# ESP32C5_RADIO register map
Vendor: Espressif; Series: ESP32-C5; File version: 0.1
Registers are 32-bit, read-write, no defined reset value unless marked. A register's access mark holds for its fields unless they carry their own. Offsets are from the block's base; [hi:lo] are bit positions; {n}, {i} and the like mark numbered series; 'fields as' and 'values as' point back to an identical list.

## MODEM_WIFI_MAC_OBSERVED (part 1 of 2) — Sparse source-qualified word views in the existing owned MMIO aperture; individual meanings and side effects remain unknown.
Base 0x600A4000
0x20 WORD_0020_OPAQUE — Opaque: meaning not established. Aligned 32-bit bus view explicitly addressed by the cited vendor source. No reset or hardware write effect is established.
  [31:0] BITS_0_31_OPAQUE — Opaque: meaning not established. Observed source use; the individual hardware meaning is unknown.
0x28 WORD_0028_OPAQUE — Opaque: meaning not established. Aligned 32-bit bus view explicitly addressed by the cited vendor source. No reset or hardware write effect is established.
  [31:16] BITS_16_31_OPAQUE — Opaque: meaning not established. Observed source use; the individual hardware meaning is unknown.
0x2C WORD_002C_OPAQUE — Opaque: meaning not established. Aligned 32-bit bus view explicitly addressed by the cited vendor source. No reset or hardware write effect is established.
  fields as WORD_0020_OPAQUE
0x38 WORD_0038_OPAQUE — Opaque: meaning not established. Aligned 32-bit bus view explicitly addressed by the cited vendor source. No reset or hardware write effect is established.
  fields as WORD_0020_OPAQUE
0x3C WORD_003C_OPAQUE — Opaque: meaning not established. Aligned 32-bit bus view explicitly addressed by the cited vendor source. No reset or hardware write effect is established.
  [23:0] BITS_0_23_OPAQUE — Opaque: meaning not established. Observed source use; the individual hardware meaning is unknown.
0x40 WORD_0040_OPAQUE ro — Opaque: meaning not established. Aligned 32-bit bus view explicitly addressed by the cited vendor source. No reset or hardware write effect is established.
  fields as WORD_0020_OPAQUE
0x44 WORD_0044_OPAQUE ro — Opaque: meaning not established. Aligned 32-bit bus view explicitly addressed by the cited vendor source. No reset or hardware write effect is established.
  fields as WORD_0020_OPAQUE
0x48 WORD_0048_OPAQUE — Opaque: meaning not established. Aligned 32-bit bus view explicitly addressed by the cited vendor source. No reset or hardware write effect is established.
  fields as WORD_0020_OPAQUE
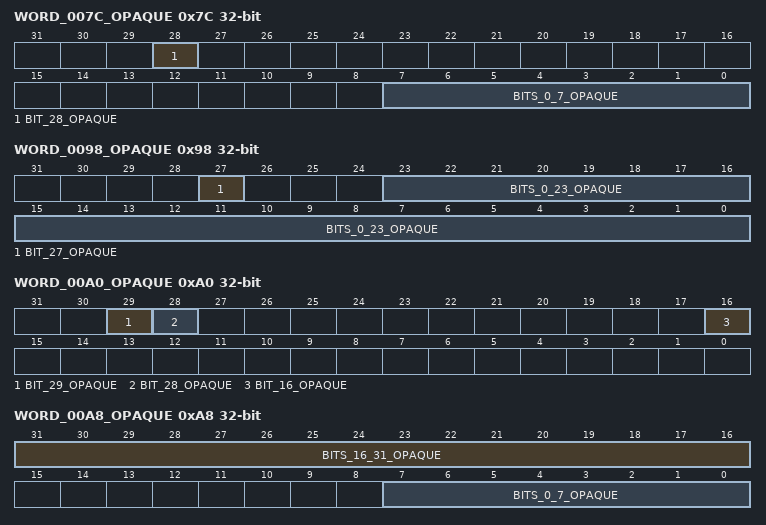
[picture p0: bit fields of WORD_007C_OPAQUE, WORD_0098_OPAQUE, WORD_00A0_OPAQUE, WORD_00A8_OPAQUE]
0x7C WORD_007C_OPAQUE — Opaque: meaning not established. Aligned 32-bit bus view explicitly addressed by the cited vendor source. No reset or hardware write effect is established.
  [28] BIT_28_OPAQUE — Opaque: meaning not established. Observed source use; the individual hardware meaning is unknown.
  [7:0] BITS_0_7_OPAQUE — Opaque: meaning not established. Observed source use; the individual hardware meaning is unknown.
0x80 WORD_0080_OPAQUE — Opaque: meaning not established. Aligned 32-bit bus view explicitly addressed by the cited vendor source. No reset or hardware write effect is established.
  fields as WORD_0020_OPAQUE
0x84 WORD_0084_OPAQUE — Opaque: meaning not established. Aligned 32-bit bus view explicitly addressed by the cited vendor source. No reset or hardware write effect is established.
  fields as WORD_0020_OPAQUE
0x88 WORD_0088_OPAQUE ro — Opaque: meaning not established. Aligned 32-bit bus view explicitly addressed by the cited vendor source. No reset or hardware write effect is established.
  fields as WORD_0020_OPAQUE
0x8C WORD_008C_OPAQUE ro — Opaque: meaning not established. Aligned 32-bit bus view explicitly addressed by the cited vendor source. No reset or hardware write effect is established.
  fields as WORD_0020_OPAQUE
0x90 WORD_0090_OPAQUE ro — Opaque: meaning not established. Aligned 32-bit bus view explicitly addressed by the cited vendor source. No reset or hardware write effect is established.
  fields as WORD_0020_OPAQUE
0x94 WORD_0094_OPAQUE ro — Opaque: meaning not established. Aligned 32-bit bus view explicitly addressed by the cited vendor source. No reset or hardware write effect is established.
  fields as WORD_0020_OPAQUE
0x98 WORD_0098_OPAQUE — Opaque: meaning not established. Aligned 32-bit bus view explicitly addressed by the cited vendor source. No reset or hardware write effect is established.
  [27] BIT_27_OPAQUE — Opaque: meaning not established. Observed source use; the individual hardware meaning is unknown.
  [23:0] BITS_0_23_OPAQUE — Opaque: meaning not established. Observed source use; the individual hardware meaning is unknown.
0x9C WORD_009C_OPAQUE — Opaque: meaning not established. Aligned 32-bit bus view explicitly addressed by the cited vendor source. No reset or hardware write effect is established.
  [3:2] BITS_2_3_OPAQUE — Opaque: meaning not established. Observed source use; the individual hardware meaning is unknown.
0xA0 WORD_00A0_OPAQUE — Opaque: meaning not established. Aligned 32-bit bus view explicitly addressed by the cited vendor source. No reset or hardware write effect is established.
  [29] BIT_29_OPAQUE — Opaque: meaning not established. Observed source use; the individual hardware meaning is unknown.
  [28] BIT_28_OPAQUE — Opaque: meaning not established. Observed source use; the individual hardware meaning is unknown.
  [16] BIT_16_OPAQUE — Opaque: meaning not established. Observed source use; the individual hardware meaning is unknown.
0xA4 WORD_00A4_OPAQUE — Opaque: meaning not established. Aligned 32-bit bus view explicitly addressed by the cited vendor source. No reset or hardware write effect is established.
  [15:12] BITS_12_15_OPAQUE — Opaque: meaning not established. Observed source use; the individual hardware meaning is unknown.
0xA8 WORD_00A8_OPAQUE ro — Opaque: meaning not established. Aligned 32-bit bus view explicitly addressed by the cited vendor source. No reset or hardware write effect is established.
  [31:16] BITS_16_31_OPAQUE — Opaque: meaning not established. Observed source use; the individual hardware meaning is unknown.
  [7:0] BITS_0_7_OPAQUE — Opaque: meaning not established. Observed source use; the individual hardware meaning is unknown.
0xAC WORD_00AC_OPAQUE ro — Opaque: meaning not established. Aligned 32-bit bus view explicitly addressed by the cited vendor source. No reset or hardware write effect is established.
  fields as WORD_0020_OPAQUE
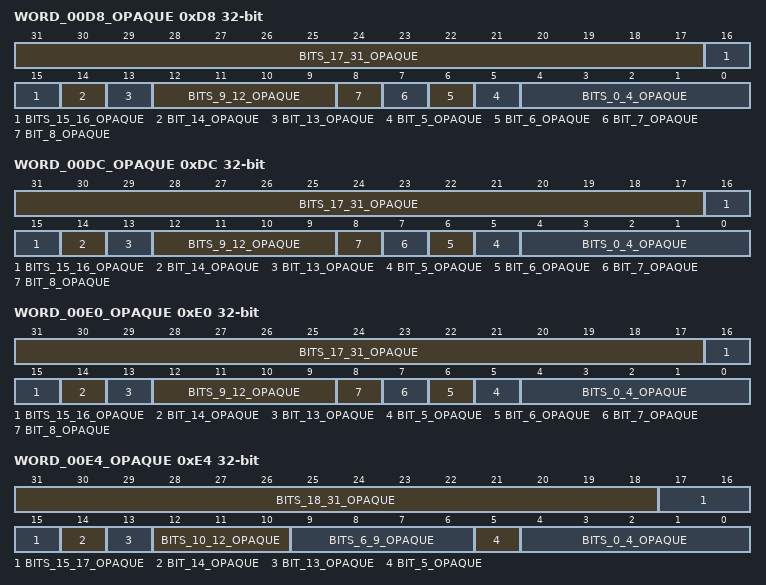
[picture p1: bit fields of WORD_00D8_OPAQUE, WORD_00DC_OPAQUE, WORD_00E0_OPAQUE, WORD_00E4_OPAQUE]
0xD8 WORD_00D8_OPAQUE — Opaque: meaning not established. Aligned 32-bit bus view explicitly addressed by the cited vendor source. No reset or hardware write effect is established.
  [31:17] BITS_17_31_OPAQUE — Opaque: meaning not established. Observed source use; the individual hardware meaning is unknown.
  [16:15] BITS_15_16_OPAQUE — Opaque: meaning not established. Observed source use; the individual hardware meaning is unknown.
  [14] BIT_14_OPAQUE — Opaque: meaning not established. Observed source use; the individual hardware meaning is unknown.
  [13] BIT_13_OPAQUE — Opaque: meaning not established. Observed source use; the individual hardware meaning is unknown.
  [12:9] BITS_9_12_OPAQUE — Opaque: meaning not established. Observed source use; the individual hardware meaning is unknown.
  [n] BIT_{n}_OPAQUE (n=5..8) — Opaque: meaning not established. Observed source use; the individual hardware meaning is unknown.
  [4:0] BITS_0_4_OPAQUE — Opaque: meaning not established. Observed source use; the individual hardware meaning is unknown.
0xDC WORD_00DC_OPAQUE — Opaque: meaning not established. Aligned 32-bit bus view explicitly addressed by the cited vendor source. No reset or hardware write effect is established.
  fields as WORD_00D8_OPAQUE
0xE0 WORD_00E0_OPAQUE — Opaque: meaning not established. Aligned 32-bit bus view explicitly addressed by the cited vendor source. No reset or hardware write effect is established.
  fields as WORD_00D8_OPAQUE
0xE4 WORD_00E4_OPAQUE — Opaque: meaning not established. Aligned 32-bit bus view explicitly addressed by the cited vendor source. No reset or hardware write effect is established.
  [31:18] BITS_18_31_OPAQUE — Opaque: meaning not established. Observed source use; the individual hardware meaning is unknown.
  [17:15] BITS_15_17_OPAQUE — Opaque: meaning not established. Observed source use; the individual hardware meaning is unknown.
  [14] BIT_14_OPAQUE — Opaque: meaning not established. Observed source use; the individual hardware meaning is unknown.
  [13] BIT_13_OPAQUE — Opaque: meaning not established. Observed source use; the individual hardware meaning is unknown.
  [12:10] BITS_10_12_OPAQUE — Opaque: meaning not established. Observed source use; the individual hardware meaning is unknown.
  [9:6] BITS_6_9_OPAQUE — Opaque: meaning not established. Observed source use; the individual hardware meaning is unknown.
  [5] BIT_5_OPAQUE — Opaque: meaning not established. Observed source use; the individual hardware meaning is unknown.
  [4:0] BITS_0_4_OPAQUE — Opaque: meaning not established. Observed source use; the individual hardware meaning is unknown.
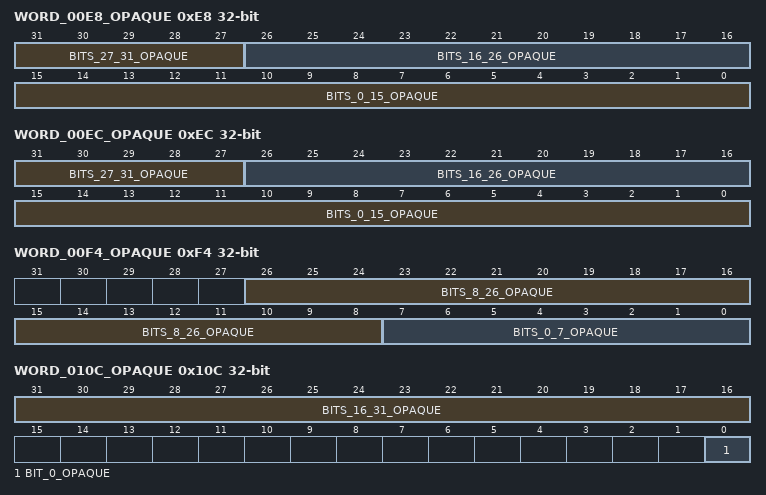
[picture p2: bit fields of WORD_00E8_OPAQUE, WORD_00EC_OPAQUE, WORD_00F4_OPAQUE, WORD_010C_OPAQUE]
0xE8 WORD_00E8_OPAQUE — Opaque: meaning not established. Aligned 32-bit bus view explicitly addressed by the cited vendor source. No reset or hardware write effect is established.
  [31:27] BITS_27_31_OPAQUE — Opaque: meaning not established. Observed source use; the individual hardware meaning is unknown.
  [26:16] BITS_16_26_OPAQUE — Opaque: meaning not established. Observed source use; the individual hardware meaning is unknown.
  [15:0] BITS_0_15_OPAQUE — Opaque: meaning not established. Observed source use; the individual hardware meaning is unknown.
0xEC WORD_00EC_OPAQUE — Opaque: meaning not established. Aligned 32-bit bus view explicitly addressed by the cited vendor source. No reset or hardware write effect is established.
  fields as WORD_00E8_OPAQUE
0xF4 WORD_00F4_OPAQUE — Opaque: meaning not established. Aligned 32-bit bus view explicitly addressed by the cited vendor source. No reset or hardware write effect is established.
  [26:8] BITS_8_26_OPAQUE — Opaque: meaning not established. Observed source use; the individual hardware meaning is unknown.
  [7:0] BITS_0_7_OPAQUE — Opaque: meaning not established. Observed source use; the individual hardware meaning is unknown.
0xFC WORD_00FC_OPAQUE — Opaque: meaning not established. Aligned 32-bit bus view explicitly addressed by the cited vendor source. No reset or hardware write effect is established.
  fields as WORD_0020_OPAQUE
0x100 WORD_0100_OPAQUE — Opaque: meaning not established. Aligned 32-bit bus view explicitly addressed by the cited vendor source. No reset or hardware write effect is established.
  fields as WORD_0020_OPAQUE
0x104 WORD_0104_OPAQUE — Opaque: meaning not established. Aligned 32-bit bus view explicitly addressed by the cited vendor source. No reset or hardware write effect is established.
  fields as WORD_0028_OPAQUE
0x108 WORD_0108_OPAQUE — Opaque: meaning not established. Aligned 32-bit bus view explicitly addressed by the cited vendor source. No reset or hardware write effect is established.
  fields as WORD_0020_OPAQUE
0x10C WORD_010C_OPAQUE — Opaque: meaning not established. Aligned 32-bit bus view explicitly addressed by the cited vendor source. No reset or hardware write effect is established.
  [31:16] BITS_16_31_OPAQUE — Opaque: meaning not established. Observed source use; the individual hardware meaning is unknown.
  [0] BIT_0_OPAQUE — Opaque: meaning not established. Observed source use; the individual hardware meaning is unknown.
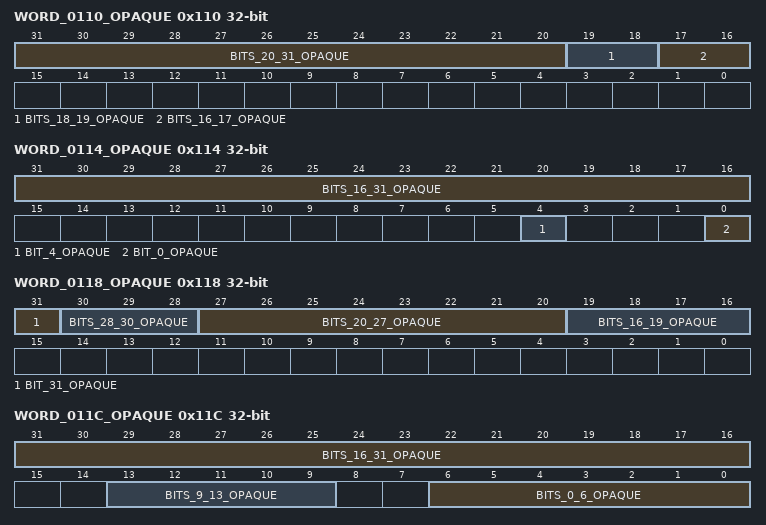
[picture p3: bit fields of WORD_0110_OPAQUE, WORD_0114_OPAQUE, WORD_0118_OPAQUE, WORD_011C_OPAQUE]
0x110 WORD_0110_OPAQUE — Opaque: meaning not established. Aligned 32-bit bus view explicitly addressed by the cited vendor source. No reset or hardware write effect is established.
  [31:20] BITS_20_31_OPAQUE — Opaque: meaning not established. Observed source use; the individual hardware meaning is unknown.
  [19:18] BITS_18_19_OPAQUE — Opaque: meaning not established. Observed source use; the individual hardware meaning is unknown.
  [17:16] BITS_16_17_OPAQUE — Opaque: meaning not established. Observed source use; the individual hardware meaning is unknown.
0x114 WORD_0114_OPAQUE — Opaque: meaning not established. Aligned 32-bit bus view explicitly addressed by the cited vendor source. No reset or hardware write effect is established.
  [31:16] BITS_16_31_OPAQUE — Opaque: meaning not established. Observed source use; the individual hardware meaning is unknown.
  [4] BIT_4_OPAQUE — Opaque: meaning not established. Observed source use; the individual hardware meaning is unknown.
  [0] BIT_0_OPAQUE — Opaque: meaning not established. Observed source use; the individual hardware meaning is unknown.
0x118 WORD_0118_OPAQUE — Opaque: meaning not established. Aligned 32-bit bus view explicitly addressed by the cited vendor source. No reset or hardware write effect is established.
  [31] BIT_31_OPAQUE — Opaque: meaning not established. Observed source use; the individual hardware meaning is unknown.
  [30:28] BITS_28_30_OPAQUE — Opaque: meaning not established. Observed source use; the individual hardware meaning is unknown.
  [27:20] BITS_20_27_OPAQUE — Opaque: meaning not established. Observed source use; the individual hardware meaning is unknown.
  [19:16] BITS_16_19_OPAQUE — Opaque: meaning not established. Observed source use; the individual hardware meaning is unknown.
0x11C WORD_011C_OPAQUE — Opaque: meaning not established. Aligned 32-bit bus view explicitly addressed by the cited vendor source. No reset or hardware write effect is established.
  [31:16] BITS_16_31_OPAQUE — Opaque: meaning not established. Observed source use; the individual hardware meaning is unknown.
  [13:9] BITS_9_13_OPAQUE — Opaque: meaning not established. Observed source use; the individual hardware meaning is unknown.
  [6:0] BITS_0_6_OPAQUE — Opaque: meaning not established. Observed source use; the individual hardware meaning is unknown.
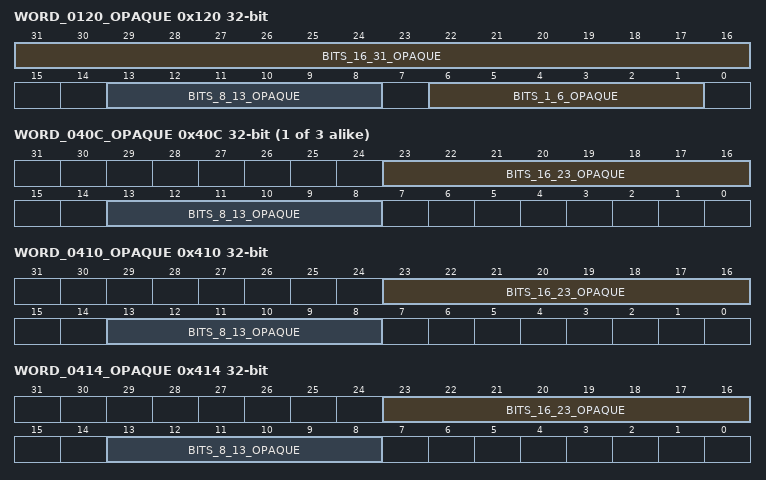
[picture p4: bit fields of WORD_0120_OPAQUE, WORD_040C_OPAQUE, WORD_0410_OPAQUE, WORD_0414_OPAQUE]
0x120 WORD_0120_OPAQUE — Opaque: meaning not established. Aligned 32-bit bus view explicitly addressed by the cited vendor source. No reset or hardware write effect is established.
  [31:16] BITS_16_31_OPAQUE — Opaque: meaning not established. Observed source use; the individual hardware meaning is unknown.
  [13:8] BITS_8_13_OPAQUE — Opaque: meaning not established. Observed source use; the individual hardware meaning is unknown.
  [6:1] BITS_1_6_OPAQUE — Opaque: meaning not established. Observed source use; the individual hardware meaning is unknown.
0x294 WORD_0294_OPAQUE — Opaque: meaning not established. Aligned 32-bit bus view explicitly addressed by the cited vendor source. No reset or hardware write effect is established.
  fields as WORD_0020_OPAQUE
0x298 WORD_0298_OPAQUE — Opaque: meaning not established. Aligned 32-bit bus view explicitly addressed by the cited vendor source. No reset or hardware write effect is established.
  fields as WORD_0020_OPAQUE
0x29C WORD_029C_OPAQUE ro — Opaque: meaning not established. Aligned 32-bit bus view explicitly addressed by the cited vendor source. No reset or hardware write effect is established.
  fields as WORD_0020_OPAQUE
0x2A0 WORD_02A0_OPAQUE ro — Opaque: meaning not established. Aligned 32-bit bus view explicitly addressed by the cited vendor source. No reset or hardware write effect is established.
  fields as WORD_0020_OPAQUE
0x2A4 WORD_02A4_OPAQUE ro — Opaque: meaning not established. Aligned 32-bit bus view explicitly addressed by the cited vendor source. No reset or hardware write effect is established.
  fields as WORD_0020_OPAQUE
0x2A8 WORD_02A8_OPAQUE ro — Opaque: meaning not established. Aligned 32-bit bus view explicitly addressed by the cited vendor source. No reset or hardware write effect is established.
  fields as WORD_0020_OPAQUE
0x2AC WORD_02AC_OPAQUE ro — Opaque: meaning not established. Aligned 32-bit bus view explicitly addressed by the cited vendor source. No reset or hardware write effect is established.
  [19:0] BITS_0_19_OPAQUE — Opaque: meaning not established. Observed source use; the individual hardware meaning is unknown.
0x2B0 WORD_02B0_OPAQUE — Opaque: meaning not established. Aligned 32-bit bus view explicitly addressed by the cited vendor source. No reset or hardware write effect is established.
  fields as WORD_0020_OPAQUE
0x2B8 WORD_02B8_OPAQUE — Opaque: meaning not established. Aligned 32-bit bus view explicitly addressed by the cited vendor source. No reset or hardware write effect is established.
  [31:30] BITS_30_31_OPAQUE — Opaque: meaning not established. Observed source use; the individual hardware meaning is unknown.
0x2FC WORD_02FC_OPAQUE — Opaque: meaning not established. Aligned 32-bit bus view explicitly addressed by the cited vendor source. No reset or hardware write effect is established.
  fields as WORD_0020_OPAQUE
0x300 WORD_0300_OPAQUE ro — Opaque: meaning not established. Aligned 32-bit bus view explicitly addressed by the cited vendor source. No reset or hardware write effect is established.
  fields as WORD_0020_OPAQUE
0x308 WORD_0308_OPAQUE — Opaque: meaning not established. Aligned 32-bit bus view explicitly addressed by the cited vendor source. No reset or hardware write effect is established.
  [1:0] BITS_0_1_OPAQUE — Opaque: meaning not established. Observed source use; the individual hardware meaning is unknown.
0x30C WORD_030C_OPAQUE ro — Opaque: meaning not established. Aligned 32-bit bus view explicitly addressed by the cited vendor source. No reset or hardware write effect is established.
  fields as WORD_0020_OPAQUE
0x310 WORD_0310_OPAQUE ro — Opaque: meaning not established. Aligned 32-bit bus view explicitly addressed by the cited vendor source. No reset or hardware write effect is established.
  [9:0] BITS_0_9_OPAQUE — Opaque: meaning not established. Observed source use; the individual hardware meaning is unknown.
0x314 WORD_0314_OPAQUE ro — Opaque: meaning not established. Aligned 32-bit bus view explicitly addressed by the cited vendor source. No reset or hardware write effect is established.
  fields as WORD_0310_OPAQUE
0x318 WORD_0318_OPAQUE — Opaque: meaning not established. Aligned 32-bit bus view explicitly addressed by the cited vendor source. No reset or hardware write effect is established.
  fields as WORD_0020_OPAQUE
{0x12C+0x10*i} WORD_{i:03}C_OPAQUE ro (i=31..34) — Opaque: meaning not established. Aligned 32-bit bus view explicitly addressed by the cited vendor source. No reset or hardware write effect is established.
  fields as WORD_0310_OPAQUE
0x320 WORD_0320_OPAQUE ro — Opaque: meaning not established. Aligned 32-bit bus view explicitly addressed by the cited vendor source. No reset or hardware write effect is established.
  fields as WORD_0310_OPAQUE
0x324 WORD_0324_OPAQUE ro — Opaque: meaning not established. Aligned 32-bit bus view explicitly addressed by the cited vendor source. No reset or hardware write effect is established.
  fields as WORD_0310_OPAQUE
0x328 WORD_0328_OPAQUE ro — Opaque: meaning not established. Aligned 32-bit bus view explicitly addressed by the cited vendor source. No reset or hardware write effect is established.
  fields as WORD_0310_OPAQUE
0x330 WORD_0330_OPAQUE ro — Opaque: meaning not established. Aligned 32-bit bus view explicitly addressed by the cited vendor source. No reset or hardware write effect is established.
  fields as WORD_0310_OPAQUE
0x334 WORD_0334_OPAQUE ro — Opaque: meaning not established. Aligned 32-bit bus view explicitly addressed by the cited vendor source. No reset or hardware write effect is established.
  fields as WORD_0310_OPAQUE
0x338 WORD_0338_OPAQUE ro — Opaque: meaning not established. Aligned 32-bit bus view explicitly addressed by the cited vendor source. No reset or hardware write effect is established.
  fields as WORD_0310_OPAQUE
0x340 WORD_0340_OPAQUE ro — Opaque: meaning not established. Aligned 32-bit bus view explicitly addressed by the cited vendor source. No reset or hardware write effect is established.
  fields as WORD_0310_OPAQUE
0x344 WORD_0344_OPAQUE ro — Opaque: meaning not established. Aligned 32-bit bus view explicitly addressed by the cited vendor source. No reset or hardware write effect is established.
  fields as WORD_0310_OPAQUE
0x348 WORD_0348_OPAQUE ro — Opaque: meaning not established. Aligned 32-bit bus view explicitly addressed by the cited vendor source. No reset or hardware write effect is established.
  [15:0] BITS_0_15_OPAQUE — Opaque: meaning not established. Observed source use; the individual hardware meaning is unknown.
0x350 WORD_0350_OPAQUE ro — Opaque: meaning not established. Aligned 32-bit bus view explicitly addressed by the cited vendor source. No reset or hardware write effect is established.
  fields as WORD_0310_OPAQUE
0x354 WORD_0354_OPAQUE ro — Opaque: meaning not established. Aligned 32-bit bus view explicitly addressed by the cited vendor source. No reset or hardware write effect is established.
  fields as WORD_0310_OPAQUE
0x358 WORD_0358_OPAQUE ro — Opaque: meaning not established. Aligned 32-bit bus view explicitly addressed by the cited vendor source. No reset or hardware write effect is established.
  fields as WORD_0310_OPAQUE
{0x12C+0x10*i} WORD_{i:03}C_OPAQUE ro (i=35..38) — Opaque: meaning not established. Aligned 32-bit bus view explicitly addressed by the cited vendor source. No reset or hardware write effect is established.
  fields as WORD_0348_OPAQUE
0x360 WORD_0360_OPAQUE ro — Opaque: meaning not established. Aligned 32-bit bus view explicitly addressed by the cited vendor source. No reset or hardware write effect is established.
  fields as WORD_0020_OPAQUE
0x364 WORD_0364_OPAQUE ro — Opaque: meaning not established. Aligned 32-bit bus view explicitly addressed by the cited vendor source. No reset or hardware write effect is established.
  fields as WORD_0348_OPAQUE
0x368 WORD_0368_OPAQUE ro — Opaque: meaning not established. Aligned 32-bit bus view explicitly addressed by the cited vendor source. No reset or hardware write effect is established.
  fields as WORD_0348_OPAQUE
0x370 WORD_0370_OPAQUE ro — Opaque: meaning not established. Aligned 32-bit bus view explicitly addressed by the cited vendor source. No reset or hardware write effect is established.
  fields as WORD_0348_OPAQUE
0x374 WORD_0374_OPAQUE ro — Opaque: meaning not established. Aligned 32-bit bus view explicitly addressed by the cited vendor source. No reset or hardware write effect is established.
  fields as WORD_0348_OPAQUE
0x378 WORD_0378_OPAQUE ro — Opaque: meaning not established. Aligned 32-bit bus view explicitly addressed by the cited vendor source. No reset or hardware write effect is established.
  fields as WORD_0348_OPAQUE
0x380 WORD_0380_OPAQUE ro — Opaque: meaning not established. Aligned 32-bit bus view explicitly addressed by the cited vendor source. No reset or hardware write effect is established.
  fields as WORD_0348_OPAQUE
0x384 WORD_0384_OPAQUE ro — Opaque: meaning not established. Aligned 32-bit bus view explicitly addressed by the cited vendor source. No reset or hardware write effect is established.
  fields as WORD_0348_OPAQUE
0x388 WORD_0388_OPAQUE ro — Opaque: meaning not established. Aligned 32-bit bus view explicitly addressed by the cited vendor source. No reset or hardware write effect is established.
  fields as WORD_0348_OPAQUE
0x390 WORD_0390_OPAQUE ro — Opaque: meaning not established. Aligned 32-bit bus view explicitly addressed by the cited vendor source. No reset or hardware write effect is established.
  fields as WORD_0348_OPAQUE
0x394 WORD_0394_OPAQUE ro — Opaque: meaning not established. Aligned 32-bit bus view explicitly addressed by the cited vendor source. No reset or hardware write effect is established.
  fields as WORD_0020_OPAQUE
0x398 WORD_0398_OPAQUE ro — Opaque: meaning not established. Aligned 32-bit bus view explicitly addressed by the cited vendor source. No reset or hardware write effect is established.
  fields as WORD_0020_OPAQUE
0x39C WORD_039C_OPAQUE ro — Opaque: meaning not established. Aligned 32-bit bus view explicitly addressed by the cited vendor source. No reset or hardware write effect is established.
  [31:24] BITS_24_31_OPAQUE — Opaque: meaning not established. Observed source use; the individual hardware meaning is unknown.
0x3A0 WORD_03A0_OPAQUE ro — Opaque: meaning not established. Aligned 32-bit bus view explicitly addressed by the cited vendor source. No reset or hardware write effect is established.
  fields as WORD_0020_OPAQUE
0x3A4 WORD_03A4_OPAQUE ro — Opaque: meaning not established. Aligned 32-bit bus view explicitly addressed by the cited vendor source. No reset or hardware write effect is established.
  fields as WORD_0020_OPAQUE
0x3A8 WORD_03A8_OPAQUE ro — Opaque: meaning not established. Aligned 32-bit bus view explicitly addressed by the cited vendor source. No reset or hardware write effect is established.
  fields as WORD_0020_OPAQUE
0x3B4 WORD_03B4_OPAQUE ro — Opaque: meaning not established. Aligned 32-bit bus view explicitly addressed by the cited vendor source. No reset or hardware write effect is established.
  fields as WORD_0020_OPAQUE
0x3B8 WORD_03B8_OPAQUE ro — Opaque: meaning not established. Aligned 32-bit bus view explicitly addressed by the cited vendor source. No reset or hardware write effect is established.
  fields as WORD_0020_OPAQUE
0x3BC WORD_03BC_OPAQUE ro — Opaque: meaning not established. Aligned 32-bit bus view explicitly addressed by the cited vendor source. No reset or hardware write effect is established.
  fields as WORD_0020_OPAQUE
0x3C0 WORD_03C0_OPAQUE ro — Opaque: meaning not established. Aligned 32-bit bus view explicitly addressed by the cited vendor source. No reset or hardware write effect is established.
  fields as WORD_0020_OPAQUE
0x400 WORD_0400_OPAQUE — Opaque: meaning not established. Aligned 32-bit bus view explicitly addressed by the cited vendor source. No reset or hardware write effect is established.
  fields as WORD_0020_OPAQUE
0x408 WORD_0408_OPAQUE — Opaque: meaning not established. Aligned 32-bit bus view explicitly addressed by the cited vendor source. No reset or hardware write effect is established.
  fields as WORD_0020_OPAQUE
{0x18C+0x10*i} WORD_{i:03}C_OPAQUE (i=40..42) — Opaque: meaning not established. Aligned 32-bit bus view explicitly addressed by the cited vendor source. No reset or hardware write effect is established.
  [23:16] BITS_16_23_OPAQUE — Opaque: meaning not established. Observed source use; the individual hardware meaning is unknown.
  [13:8] BITS_8_13_OPAQUE — Opaque: meaning not established. Observed source use; the individual hardware meaning is unknown.
0x410 WORD_0410_OPAQUE — Opaque: meaning not established. Aligned 32-bit bus view explicitly addressed by the cited vendor source. No reset or hardware write effect is established.
  fields as WORD_040C_OPAQUE
0x414 WORD_0414_OPAQUE — Opaque: meaning not established. Aligned 32-bit bus view explicitly addressed by the cited vendor source. No reset or hardware write effect is established.
  fields as WORD_040C_OPAQUE
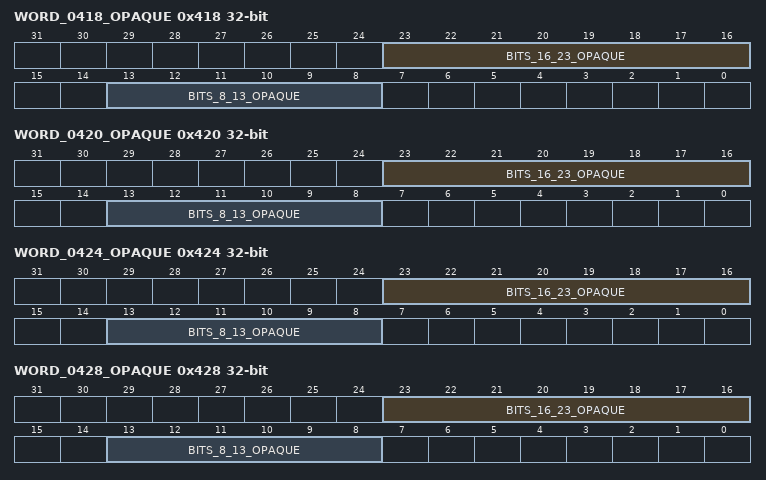
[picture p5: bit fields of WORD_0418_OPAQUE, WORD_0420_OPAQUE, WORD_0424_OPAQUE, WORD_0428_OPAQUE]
0x418 WORD_0418_OPAQUE — Opaque: meaning not established. Aligned 32-bit bus view explicitly addressed by the cited vendor source. No reset or hardware write effect is established.
  fields as WORD_040C_OPAQUE
0x420 WORD_0420_OPAQUE — Opaque: meaning not established. Aligned 32-bit bus view explicitly addressed by the cited vendor source. No reset or hardware write effect is established.
  fields as WORD_040C_OPAQUE
0x424 WORD_0424_OPAQUE — Opaque: meaning not established. Aligned 32-bit bus view explicitly addressed by the cited vendor source. No reset or hardware write effect is established.
  fields as WORD_040C_OPAQUE
0x428 WORD_0428_OPAQUE — Opaque: meaning not established. Aligned 32-bit bus view explicitly addressed by the cited vendor source. No reset or hardware write effect is established.
  fields as WORD_040C_OPAQUE
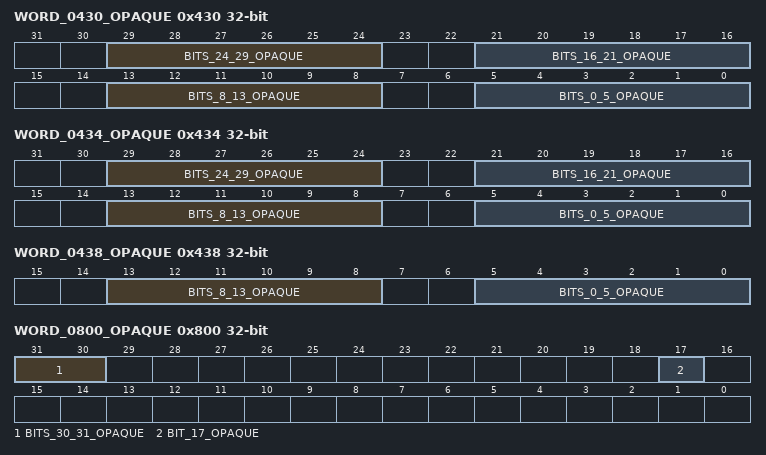
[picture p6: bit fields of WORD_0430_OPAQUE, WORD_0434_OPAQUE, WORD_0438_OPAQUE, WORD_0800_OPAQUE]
0x430 WORD_0430_OPAQUE — Opaque: meaning not established. Aligned 32-bit bus view explicitly addressed by the cited vendor source. No reset or hardware write effect is established.
  [29:24] BITS_24_29_OPAQUE — Opaque: meaning not established. Observed source use; the individual hardware meaning is unknown.
  [21:16] BITS_16_21_OPAQUE — Opaque: meaning not established. Observed source use; the individual hardware meaning is unknown.
  [13:8] BITS_8_13_OPAQUE — Opaque: meaning not established. Observed source use; the individual hardware meaning is unknown.
  [5:0] BITS_0_5_OPAQUE — Opaque: meaning not established. Observed source use; the individual hardware meaning is unknown.
0x434 WORD_0434_OPAQUE — Opaque: meaning not established. Aligned 32-bit bus view explicitly addressed by the cited vendor source. No reset or hardware write effect is established.
  fields as WORD_0430_OPAQUE
0x438 WORD_0438_OPAQUE — Opaque: meaning not established. Aligned 32-bit bus view explicitly addressed by the cited vendor source. No reset or hardware write effect is established.
  [13:8] BITS_8_13_OPAQUE — Opaque: meaning not established. Observed source use; the individual hardware meaning is unknown.
  [5:0] BITS_0_5_OPAQUE — Opaque: meaning not established. Observed source use; the individual hardware meaning is unknown.
0x43C WORD_043C_OPAQUE — Opaque: meaning not established. Aligned 32-bit bus view explicitly addressed by the cited vendor source. No reset or hardware write effect is established.
  fields as WORD_0020_OPAQUE
0x440 WORD_0440_OPAQUE — Opaque: meaning not established. Aligned 32-bit bus view explicitly addressed by the cited vendor source. No reset or hardware write effect is established.
  fields as WORD_0020_OPAQUE
0x444 WORD_0444_OPAQUE — Opaque: meaning not established. Aligned 32-bit bus view explicitly addressed by the cited vendor source. No reset or hardware write effect is established.
  fields as WORD_0020_OPAQUE
0x448 WORD_0448_OPAQUE — Opaque: meaning not established. Aligned 32-bit bus view explicitly addressed by the cited vendor source. No reset or hardware write effect is established.
  fields as WORD_0020_OPAQUE
0x44C WORD_044C_OPAQUE — Opaque: meaning not established. Aligned 32-bit bus view explicitly addressed by the cited vendor source. No reset or hardware write effect is established.
  fields as WORD_0020_OPAQUE
0x458 WORD_0458_OPAQUE — Opaque: meaning not established. Aligned 32-bit bus view explicitly addressed by the cited vendor source. No reset or hardware write effect is established.
  fields as WORD_0020_OPAQUE
0x464 WORD_0464_OPAQUE — Opaque: meaning not established. Aligned 32-bit bus view explicitly addressed by the cited vendor source. No reset or hardware write effect is established.
  fields as WORD_0020_OPAQUE
0x47C WORD_047C_OPAQUE — Opaque: meaning not established. Aligned 32-bit bus view explicitly addressed by the cited vendor source. No reset or hardware write effect is established.
  [23:12] BITS_12_23_OPAQUE — Opaque: meaning not established. Observed source use; the individual hardware meaning is unknown.
0x480 WORD_0480_OPAQUE — Opaque: meaning not established. Aligned 32-bit bus view explicitly addressed by the cited vendor source. No reset or hardware write effect is established.
  [31] BIT_31_OPAQUE — Opaque: meaning not established. Observed source use; the individual hardware meaning is unknown.
0x48C WORD_048C_OPAQUE — Opaque: meaning not established. Aligned 32-bit bus view explicitly addressed by the cited vendor source. No reset or hardware write effect is established.
  fields as WORD_0020_OPAQUE
0x490 WORD_0490_OPAQUE — Opaque: meaning not established. Aligned 32-bit bus view explicitly addressed by the cited vendor source. No reset or hardware write effect is established.
  [31:18] BITS_18_31_OPAQUE — Opaque: meaning not established. Observed source use; the individual hardware meaning is unknown.
0x494 WORD_0494_OPAQUE — Opaque: meaning not established. Aligned 32-bit bus view explicitly addressed by the cited vendor source. No reset or hardware write effect is established.
  [15] BIT_15_OPAQUE — Opaque: meaning not established. Observed source use; the individual hardware meaning is unknown.
0x4C4 WORD_04C4_OPAQUE — Opaque: meaning not established. Aligned 32-bit bus view explicitly addressed by the cited vendor source. No reset or hardware write effect is established.
  [29:0] BITS_0_29_OPAQUE — Opaque: meaning not established. Observed source use; the individual hardware meaning is unknown.
0x4C8 WORD_04C8_OPAQUE — Opaque: meaning not established. Aligned 32-bit bus view explicitly addressed by the cited vendor source. No reset or hardware write effect is established.
  [27:0] BITS_0_27_OPAQUE — Opaque: meaning not established. Observed source use; the individual hardware meaning is unknown.
0x4CC WORD_04CC_OPAQUE — Opaque: meaning not established. Aligned 32-bit bus view explicitly addressed by the cited vendor source. No reset or hardware write effect is established.
  fields as WORD_0020_OPAQUE
0x4D0 WORD_04D0_OPAQUE — Opaque: meaning not established. Aligned 32-bit bus view explicitly addressed by the cited vendor source. No reset or hardware write effect is established.
  [30:0] BITS_0_30_OPAQUE — Opaque: meaning not established. Observed source use; the individual hardware meaning is unknown.
0x4D4 WORD_04D4_OPAQUE — Opaque: meaning not established. Aligned 32-bit bus view explicitly addressed by the cited vendor source. No reset or hardware write effect is established.
  fields as WORD_0020_OPAQUE
0x4EC WORD_04EC_OPAQUE ro — Opaque: meaning not established. Aligned 32-bit bus view explicitly addressed by the cited vendor source. No reset or hardware write effect is established.
  [25:16] BITS_16_25_OPAQUE — Opaque: meaning not established. Observed source use; the individual hardware meaning is unknown.
0x4F0 WORD_04F0_OPAQUE ro — Opaque: meaning not established. Aligned 32-bit bus view explicitly addressed by the cited vendor source. No reset or hardware write effect is established.
  fields as WORD_0020_OPAQUE
0x800 WORD_0800_OPAQUE — Opaque: meaning not established. Aligned 32-bit bus view explicitly addressed by the cited vendor source. No reset or hardware write effect is established.
  [31:30] BITS_30_31_OPAQUE — Opaque: meaning not established. Observed source use; the individual hardware meaning is unknown.
  [17] BIT_17_OPAQUE — Opaque: meaning not established. Observed source use; the individual hardware meaning is unknown.
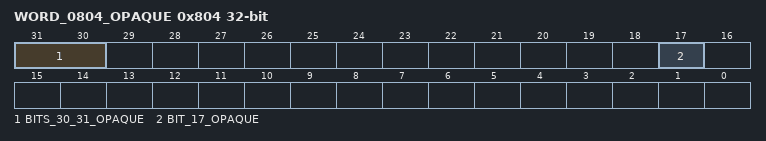
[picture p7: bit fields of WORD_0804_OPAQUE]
0x804 WORD_0804_OPAQUE — Opaque: meaning not established. Aligned 32-bit bus view explicitly addressed by the cited vendor source. No reset or hardware write effect is established.
  fields as WORD_0800_OPAQUE
0x808 WORD_0808_OPAQUE — Opaque: meaning not established. Aligned source-qualified 32-bit bus view in the existing owned aperture. No reset, safe transaction or read safety is established.
  fields as WORD_02B8_OPAQUE
0x810 WORD_0810_OPAQUE — Opaque: meaning not established. Aligned 32-bit bus view explicitly addressed by the cited vendor source. No reset or hardware write effect is established.
  [21:6] BITS_6_21_OPAQUE — Opaque: meaning not established. Observed source use; the individual hardware meaning is unknown.
